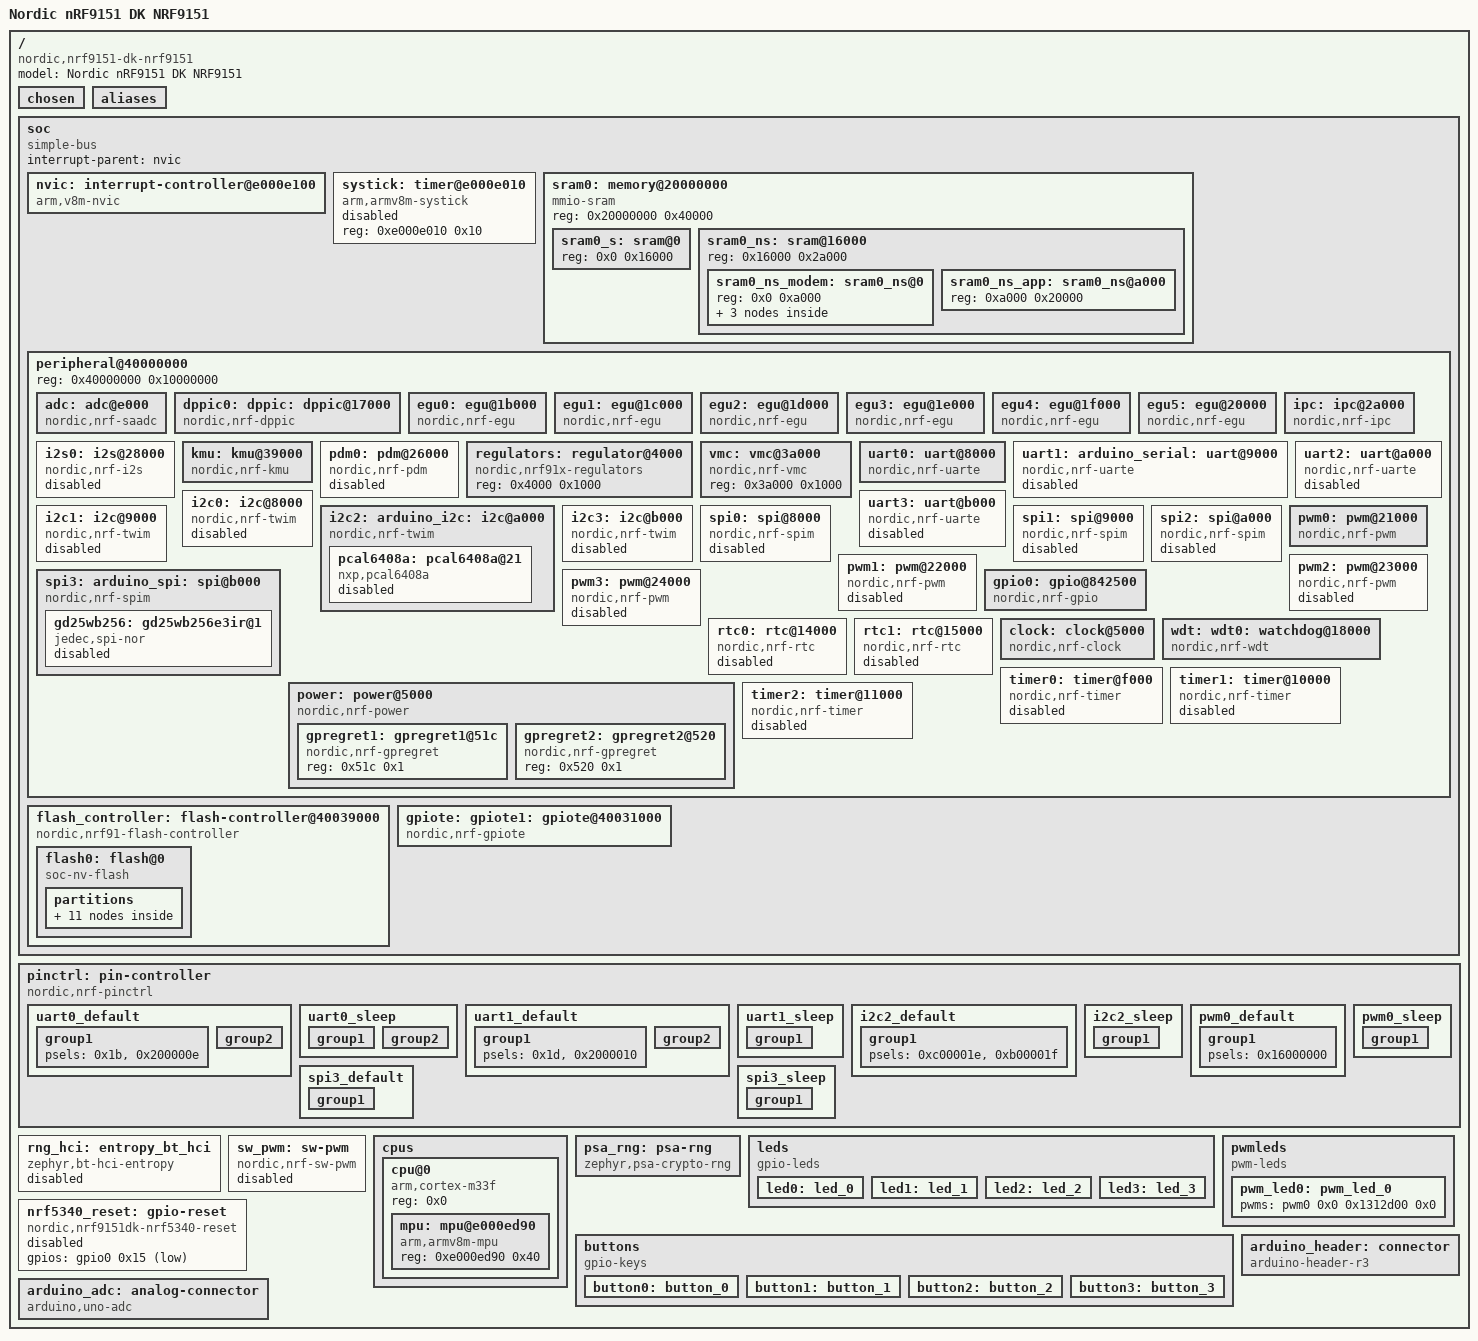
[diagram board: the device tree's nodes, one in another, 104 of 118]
/dts-v1/;

/* node '/' defined in zephyr/dts/common/skeleton.dtsi:9 */
/ {
	#address-cells = < 0x1 >;                 /* in zephyr/dts/common/skeleton.dtsi:10 */
	#size-cells = < 0x1 >;                    /* in zephyr/dts/common/skeleton.dtsi:11 */
	model = "Nordic nRF9151 DK NRF9151";      /* in zephyr/boards/nordic/nrf9151dk/nrf9151dk_nrf9151_common.dtsi:11 */
	compatible = "nordic,nrf9151-dk-nrf9151"; /* in zephyr/boards/nordic/nrf9151dk/nrf9151dk_nrf9151_common.dtsi:12 */

	/* node '/chosen' defined in zephyr/dts/common/skeleton.dtsi:13 */
	chosen {
		zephyr,entropy = &psa_rng;                   /* in zephyr/dts/arm/nordic/nrf91_ns.dtsi:31 */
		zephyr,flash-controller = &flash_controller; /* in zephyr/dts/arm/nordic/nrf91_ns.dtsi:32 */
		zephyr,console = &uart0;                     /* in zephyr/boards/nordic/nrf9151dk/nrf9151dk_nrf9151_common.dtsi:15 */
		zephyr,shell-uart = &uart0;                  /* in zephyr/boards/nordic/nrf9151dk/nrf9151dk_nrf9151_common.dtsi:16 */
		zephyr,uart-mcumgr = &uart0;                 /* in zephyr/boards/nordic/nrf9151dk/nrf9151dk_nrf9151_common.dtsi:17 */
		zephyr,flash = &flash0;                      /* in zephyr/boards/nordic/nrf9151dk/nrf9151dk_nrf9151_ns.dts:13 */
		zephyr,sram = &sram0_ns_app;                 /* in zephyr/boards/nordic/nrf9151dk/nrf9151dk_nrf9151_ns.dts:14 */
		zephyr,code-partition = &slot0_ns_partition; /* in zephyr/boards/nordic/nrf9151dk/nrf9151dk_nrf9151_ns.dts:15 */
	};

	/* node '/aliases' defined in zephyr/dts/common/skeleton.dtsi:15 */
	aliases {
		led0 = &led0;               /* in zephyr/boards/nordic/nrf9151dk/nrf9151dk_nrf9151_common.dtsi:128 */
		led1 = &led1;               /* in zephyr/boards/nordic/nrf9151dk/nrf9151dk_nrf9151_common.dtsi:129 */
		led2 = &led2;               /* in zephyr/boards/nordic/nrf9151dk/nrf9151dk_nrf9151_common.dtsi:130 */
		led3 = &led3;               /* in zephyr/boards/nordic/nrf9151dk/nrf9151dk_nrf9151_common.dtsi:131 */
		pwm-led0 = &pwm_led0;       /* in zephyr/boards/nordic/nrf9151dk/nrf9151dk_nrf9151_common.dtsi:132 */
		sw0 = &button0;             /* in zephyr/boards/nordic/nrf9151dk/nrf9151dk_nrf9151_common.dtsi:133 */
		sw1 = &button1;             /* in zephyr/boards/nordic/nrf9151dk/nrf9151dk_nrf9151_common.dtsi:134 */
		sw2 = &button2;             /* in zephyr/boards/nordic/nrf9151dk/nrf9151dk_nrf9151_common.dtsi:135 */
		sw3 = &button3;             /* in zephyr/boards/nordic/nrf9151dk/nrf9151dk_nrf9151_common.dtsi:136 */
		mcuboot-button0 = &button0; /* in zephyr/boards/nordic/nrf9151dk/nrf9151dk_nrf9151_common.dtsi:137 */
		mcuboot-led0 = &led0;       /* in zephyr/boards/nordic/nrf9151dk/nrf9151dk_nrf9151_common.dtsi:138 */
		watchdog0 = &wdt0;          /* in zephyr/boards/nordic/nrf9151dk/nrf9151dk_nrf9151_common.dtsi:139 */
	};

	/* node '/soc' defined in zephyr/dts/arm/armv8-m.dtsi:6 */
	soc {
		#address-cells = < 0x1 >;     /* in zephyr/dts/arm/armv8-m.dtsi:7 */
		#size-cells = < 0x1 >;        /* in zephyr/dts/arm/armv8-m.dtsi:8 */
		interrupt-parent = < &nvic >; /* in zephyr/dts/arm/armv8-m.dtsi:10 */
		ranges;                       /* in zephyr/dts/arm/armv8-m.dtsi:11 */
		compatible = "simple-bus";    /* in zephyr/dts/arm/nordic/nrf91_ns.dtsi:36 */

		/* node '/soc/interrupt-controller@e000e100' defined in zephyr/dts/arm/armv8-m.dtsi:13 */
		nvic: interrupt-controller@e000e100 {
			#address-cells = < 0x1 >;            /* in zephyr/dts/arm/armv8-m.dtsi:14 */
			compatible = "arm,v8m-nvic";         /* in zephyr/dts/arm/armv8-m.dtsi:15 */
			reg = < 0xe000e100 0xc00 >;          /* in zephyr/dts/arm/armv8-m.dtsi:16 */
			interrupt-controller;                /* in zephyr/dts/arm/armv8-m.dtsi:17 */
			#interrupt-cells = < 0x2 >;          /* in zephyr/dts/arm/armv8-m.dtsi:18 */
			arm,num-irq-priority-bits = < 0x3 >; /* in zephyr/dts/arm/nordic/nrf91_ns.dtsi:95 */
			phandle = < 0x1 >;                   /* in zephyr/dts/arm/armv8-m.dtsi:10 */
		};

		/* node '/soc/timer@e000e010' defined in zephyr/dts/arm/armv8-m.dtsi:21 */
		systick: timer@e000e010 {
			compatible = "arm,armv8m-systick"; /* in zephyr/dts/arm/armv8-m.dtsi:22 */
			reg = < 0xe000e010 0x10 >;         /* in zephyr/dts/arm/armv8-m.dtsi:23 */
			status = "disabled";               /* in zephyr/dts/arm/nordic/nrf91_ns.dtsi:100 */
		};

		/* node '/soc/memory@20000000' defined in zephyr/dts/arm/nordic/nrf91_ns.dtsi:38 */
		sram0: memory@20000000 {
			compatible = "mmio-sram";            /* in zephyr/dts/arm/nordic/nrf91_ns.dtsi:39 */
			#address-cells = < 0x1 >;            /* in zephyr/dts/arm/nordic/nrf91_ns.dtsi:40 */
			#size-cells = < 0x1 >;               /* in zephyr/dts/arm/nordic/nrf91_ns.dtsi:41 */
			reg = < 0x20000000 0x40000 >;        /* in zephyr/dts/arm/nordic/nrf9151_ns_laca.dtsi:11 */
			ranges = < 0x0 0x20000000 0x40000 >; /* in zephyr/dts/arm/nordic/nrf9151_ns_laca.dtsi:12 */

			/* node '/soc/memory@20000000/sram@0' defined in zephyr/dts/vendor/nordic/nrf91xx_partition.dtsi:116 */
			sram0_s: sram@0 {
				reg = < 0x0 0x16000 >; /* in zephyr/dts/vendor/nordic/nrf91xx_partition.dtsi:118 */
			};

			/* node '/soc/memory@20000000/sram@16000' defined in zephyr/dts/vendor/nordic/nrf91xx_partition.dtsi:121 */
			sram0_ns: sram@16000 {
				reg = < 0x16000 0x2a000 >;        /* in zephyr/dts/vendor/nordic/nrf91xx_partition.dtsi:123 */
				#address-cells = < 0x1 >;         /* in zephyr/dts/vendor/nordic/nrf91xx_partition.dtsi:124 */
				#size-cells = < 0x1 >;            /* in zephyr/dts/vendor/nordic/nrf91xx_partition.dtsi:125 */
				ranges = < 0x0 0x16000 0x2a000 >; /* in zephyr/dts/vendor/nordic/nrf91xx_partition.dtsi:126 */

				/* node '/soc/memory@20000000/sram@16000/sram0_ns@0' defined in zephyr/dts/vendor/nordic/nrf91xx_partition.dtsi:128 */
				sram0_ns_modem: sram0_ns@0 {
					reg = < 0x0 0xa000 >;        /* in zephyr/dts/vendor/nordic/nrf91xx_partition.dtsi:130 */
					#address-cells = < 0x1 >;    /* in zephyr/dts/vendor/nordic/nrf91xx_partition.dtsi:131 */
					#size-cells = < 0x1 >;       /* in zephyr/dts/vendor/nordic/nrf91xx_partition.dtsi:132 */
					ranges = < 0x0 0x0 0xa000 >; /* in zephyr/dts/vendor/nordic/nrf91xx_partition.dtsi:133 */

					/* node '/soc/memory@20000000/sram@16000/sram0_ns@0/sram0_ns_modem@0' defined in zephyr/dts/vendor/nordic/nrf91xx_partition.dtsi:135 */
					cpuapp_cpucell_ipc_shm_ctrl: sram0_ns_modem@0 {
						reg = < 0x0 0x4e8 >; /* in zephyr/dts/vendor/nordic/nrf91xx_partition.dtsi:137 */
					};

					/* node '/soc/memory@20000000/sram@16000/sram0_ns@0/sram0_ns_modem@4e8' defined in zephyr/dts/vendor/nordic/nrf91xx_partition.dtsi:140 */
					cpuapp_cpucell_ipc_shm_heap: sram0_ns_modem@4e8 {
						reg = < 0x4e8 0x2080 >; /* in zephyr/dts/vendor/nordic/nrf91xx_partition.dtsi:142 */
					};

					/* node '/soc/memory@20000000/sram@16000/sram0_ns@0/sram0_ns_modem@2568' defined in zephyr/dts/vendor/nordic/nrf91xx_partition.dtsi:145 */
					cpucell_cpuapp_ipc_shm_heap: sram0_ns_modem@2568 {
						reg = < 0x2568 0x2000 >; /* in zephyr/dts/vendor/nordic/nrf91xx_partition.dtsi:147 */
					};
				};

				/* node '/soc/memory@20000000/sram@16000/sram0_ns@a000' defined in zephyr/dts/vendor/nordic/nrf91xx_partition.dtsi:151 */
				sram0_ns_app: sram0_ns@a000 {
					reg = < 0xa000 0x20000 >; /* in zephyr/dts/vendor/nordic/nrf91xx_partition.dtsi:153 */
				};
			};
		};

		/* node '/soc/peripheral@40000000' defined in zephyr/dts/arm/nordic/nrf91_ns.dtsi:44 */
		peripheral@40000000 {
			#address-cells = < 0x1 >;               /* in zephyr/dts/arm/nordic/nrf91_ns.dtsi:45 */
			#size-cells = < 0x1 >;                  /* in zephyr/dts/arm/nordic/nrf91_ns.dtsi:46 */
			reg = < 0x40000000 0x10000000 >;        /* in zephyr/dts/arm/nordic/nrf91_ns.dtsi:47 */
			ranges = < 0x0 0x40000000 0x10000000 >; /* in zephyr/dts/arm/nordic/nrf91_ns.dtsi:48 */

			/* node '/soc/peripheral@40000000/adc@e000' defined in zephyr/dts/arm/nordic/nrf91_peripherals.dtsi:7 */
			adc: adc@e000 {
				compatible = "nordic,nrf-saadc"; /* in zephyr/dts/arm/nordic/nrf91_peripherals.dtsi:8 */
				reg = < 0xe000 0x1000 >;         /* in zephyr/dts/arm/nordic/nrf91_peripherals.dtsi:9 */
				interrupts = < 0xe 0x1 >;        /* in zephyr/dts/arm/nordic/nrf91_peripherals.dtsi:10 */
				#io-channel-cells = < 0x1 >;     /* in zephyr/dts/arm/nordic/nrf91_peripherals.dtsi:12 */
				zephyr,pm-device-runtime-auto;   /* in zephyr/dts/arm/nordic/nrf91_peripherals.dtsi:13 */
				status = "okay";                 /* in zephyr/boards/nordic/nrf9151dk/nrf9151dk_nrf9151_common.dtsi:144 */
				phandle = < 0x11 >;              /* in zephyr/boards/nordic/nrf9151dk/nrf9151dk_nrf9151_common.dtsi:118 */
			};

			/* node '/soc/peripheral@40000000/dppic@17000' defined in zephyr/dts/arm/nordic/nrf91_peripherals.dtsi:16 */
			dppic0: dppic: dppic@17000 {
				compatible = "nordic,nrf-dppic"; /* in zephyr/dts/arm/nordic/nrf91_peripherals.dtsi:17 */
				reg = < 0x17000 0x1000 >;        /* in zephyr/dts/arm/nordic/nrf91_peripherals.dtsi:18 */
				status = "okay";                 /* in zephyr/dts/arm/nordic/nrf91_peripherals.dtsi:19 */
				channels = < 0x10 >;             /* in zephyr/dts/arm/nordic/nrf91_peripherals.dtsi:20 */
				groups = < 0x6 >;                /* in zephyr/dts/arm/nordic/nrf91_peripherals.dtsi:21 */
			};

			/* node '/soc/peripheral@40000000/egu@1b000' defined in zephyr/dts/arm/nordic/nrf91_peripherals.dtsi:24 */
			egu0: egu@1b000 {
				compatible = "nordic,nrf-egu"; /* in zephyr/dts/arm/nordic/nrf91_peripherals.dtsi:25 */
				reg = < 0x1b000 0x1000 >;      /* in zephyr/dts/arm/nordic/nrf91_peripherals.dtsi:26 */
				interrupts = < 0x1b 0x1 >;     /* in zephyr/dts/arm/nordic/nrf91_peripherals.dtsi:27 */
				status = "okay";               /* in zephyr/dts/arm/nordic/nrf91_peripherals.dtsi:28 */
			};

			/* node '/soc/peripheral@40000000/egu@1c000' defined in zephyr/dts/arm/nordic/nrf91_peripherals.dtsi:31 */
			egu1: egu@1c000 {
				compatible = "nordic,nrf-egu"; /* in zephyr/dts/arm/nordic/nrf91_peripherals.dtsi:32 */
				reg = < 0x1c000 0x1000 >;      /* in zephyr/dts/arm/nordic/nrf91_peripherals.dtsi:33 */
				interrupts = < 0x1c 0x1 >;     /* in zephyr/dts/arm/nordic/nrf91_peripherals.dtsi:34 */
				status = "okay";               /* in zephyr/dts/arm/nordic/nrf91_peripherals.dtsi:35 */
			};

			/* node '/soc/peripheral@40000000/egu@1d000' defined in zephyr/dts/arm/nordic/nrf91_peripherals.dtsi:38 */
			egu2: egu@1d000 {
				compatible = "nordic,nrf-egu"; /* in zephyr/dts/arm/nordic/nrf91_peripherals.dtsi:39 */
				reg = < 0x1d000 0x1000 >;      /* in zephyr/dts/arm/nordic/nrf91_peripherals.dtsi:40 */
				interrupts = < 0x1d 0x1 >;     /* in zephyr/dts/arm/nordic/nrf91_peripherals.dtsi:41 */
				status = "okay";               /* in zephyr/dts/arm/nordic/nrf91_peripherals.dtsi:42 */
			};

			/* node '/soc/peripheral@40000000/egu@1e000' defined in zephyr/dts/arm/nordic/nrf91_peripherals.dtsi:45 */
			egu3: egu@1e000 {
				compatible = "nordic,nrf-egu"; /* in zephyr/dts/arm/nordic/nrf91_peripherals.dtsi:46 */
				reg = < 0x1e000 0x1000 >;      /* in zephyr/dts/arm/nordic/nrf91_peripherals.dtsi:47 */
				interrupts = < 0x1e 0x1 >;     /* in zephyr/dts/arm/nordic/nrf91_peripherals.dtsi:48 */
				status = "okay";               /* in zephyr/dts/arm/nordic/nrf91_peripherals.dtsi:49 */
			};

			/* node '/soc/peripheral@40000000/egu@1f000' defined in zephyr/dts/arm/nordic/nrf91_peripherals.dtsi:52 */
			egu4: egu@1f000 {
				compatible = "nordic,nrf-egu"; /* in zephyr/dts/arm/nordic/nrf91_peripherals.dtsi:53 */
				reg = < 0x1f000 0x1000 >;      /* in zephyr/dts/arm/nordic/nrf91_peripherals.dtsi:54 */
				interrupts = < 0x1f 0x1 >;     /* in zephyr/dts/arm/nordic/nrf91_peripherals.dtsi:55 */
				status = "okay";               /* in zephyr/dts/arm/nordic/nrf91_peripherals.dtsi:56 */
			};

			/* node '/soc/peripheral@40000000/egu@20000' defined in zephyr/dts/arm/nordic/nrf91_peripherals.dtsi:59 */
			egu5: egu@20000 {
				compatible = "nordic,nrf-egu"; /* in zephyr/dts/arm/nordic/nrf91_peripherals.dtsi:60 */
				reg = < 0x20000 0x1000 >;      /* in zephyr/dts/arm/nordic/nrf91_peripherals.dtsi:61 */
				interrupts = < 0x20 0x1 >;     /* in zephyr/dts/arm/nordic/nrf91_peripherals.dtsi:62 */
				status = "okay";               /* in zephyr/dts/arm/nordic/nrf91_peripherals.dtsi:63 */
			};

			/* node '/soc/peripheral@40000000/ipc@2a000' defined in zephyr/dts/arm/nordic/nrf91_peripherals.dtsi:66 */
			ipc: ipc@2a000 {
				compatible = "nordic,nrf-ipc"; /* in zephyr/dts/arm/nordic/nrf91_peripherals.dtsi:67 */
				reg = < 0x2a000 0x1000 >;      /* in zephyr/dts/arm/nordic/nrf91_peripherals.dtsi:68 */
				interrupts = < 0x2a 0x1 >;     /* in zephyr/dts/arm/nordic/nrf91_peripherals.dtsi:69 */
				status = "okay";               /* in zephyr/dts/arm/nordic/nrf91_peripherals.dtsi:70 */
			};

			/* node '/soc/peripheral@40000000/i2s@28000' defined in zephyr/dts/arm/nordic/nrf91_peripherals.dtsi:73 */
			i2s0: i2s@28000 {
				compatible = "nordic,nrf-i2s"; /* in zephyr/dts/arm/nordic/nrf91_peripherals.dtsi:74 */
				#address-cells = < 0x1 >;      /* in zephyr/dts/arm/nordic/nrf91_peripherals.dtsi:75 */
				#size-cells = < 0x0 >;         /* in zephyr/dts/arm/nordic/nrf91_peripherals.dtsi:76 */
				reg = < 0x28000 0x1000 >;      /* in zephyr/dts/arm/nordic/nrf91_peripherals.dtsi:77 */
				interrupts = < 0x28 0x1 >;     /* in zephyr/dts/arm/nordic/nrf91_peripherals.dtsi:78 */
				status = "disabled";           /* in zephyr/dts/arm/nordic/nrf91_peripherals.dtsi:79 */
			};

			/* node '/soc/peripheral@40000000/kmu@39000' defined in zephyr/dts/arm/nordic/nrf91_peripherals.dtsi:82 */
			kmu: kmu@39000 {
				compatible = "nordic,nrf-kmu"; /* in zephyr/dts/arm/nordic/nrf91_peripherals.dtsi:83 */
				reg = < 0x39000 0x1000 >;      /* in zephyr/dts/arm/nordic/nrf91_peripherals.dtsi:84 */
				interrupts = < 0x39 0x1 >;     /* in zephyr/dts/arm/nordic/nrf91_peripherals.dtsi:85 */
				status = "okay";               /* in zephyr/dts/arm/nordic/nrf91_peripherals.dtsi:86 */
			};

			/* node '/soc/peripheral@40000000/pdm@26000' defined in zephyr/dts/arm/nordic/nrf91_peripherals.dtsi:89 */
			pdm0: pdm@26000 {
				compatible = "nordic,nrf-pdm"; /* in zephyr/dts/arm/nordic/nrf91_peripherals.dtsi:90 */
				reg = < 0x26000 0x1000 >;      /* in zephyr/dts/arm/nordic/nrf91_peripherals.dtsi:91 */
				interrupts = < 0x26 0x1 >;     /* in zephyr/dts/arm/nordic/nrf91_peripherals.dtsi:92 */
				status = "disabled";           /* in zephyr/dts/arm/nordic/nrf91_peripherals.dtsi:93 */
			};

			/* node '/soc/peripheral@40000000/regulator@4000' defined in zephyr/dts/arm/nordic/nrf91_peripherals.dtsi:96 */
			regulators: regulator@4000 {
				compatible = "nordic,nrf91x-regulators"; /* in zephyr/dts/arm/nordic/nrf91_peripherals.dtsi:97 */
				reg = < 0x4000 0x1000 >;                 /* in zephyr/dts/arm/nordic/nrf91_peripherals.dtsi:98 */
				status = "okay";                         /* in zephyr/dts/arm/nordic/nrf91_peripherals.dtsi:99 */
			};

			/* node '/soc/peripheral@40000000/vmc@3a000' defined in zephyr/dts/arm/nordic/nrf91_peripherals.dtsi:102 */
			vmc: vmc@3a000 {
				compatible = "nordic,nrf-vmc"; /* in zephyr/dts/arm/nordic/nrf91_peripherals.dtsi:103 */
				reg = < 0x3a000 0x1000 >;      /* in zephyr/dts/arm/nordic/nrf91_peripherals.dtsi:104 */
				status = "okay";               /* in zephyr/dts/arm/nordic/nrf91_peripherals.dtsi:105 */
			};

			/* node '/soc/peripheral@40000000/uart@8000' defined in zephyr/dts/arm/nordic/nrf91_peripherals.dtsi:108 */
			uart0: uart@8000 {
				compatible = "nordic,nrf-uarte"; /* in zephyr/dts/arm/nordic/nrf91_peripherals.dtsi:109 */
				reg = < 0x8000 0x1000 >;         /* in zephyr/dts/arm/nordic/nrf91_peripherals.dtsi:110 */
				interrupts = < 0x8 0x1 >;        /* in zephyr/dts/arm/nordic/nrf91_peripherals.dtsi:111 */
				status = "okay";                 /* in zephyr/boards/nordic/nrf9151dk/nrf9151dk_nrf9151_common.dtsi:156 */
				current-speed = < 0x1c200 >;     /* in zephyr/boards/nordic/nrf9151dk/nrf9151dk_nrf9151_common.dtsi:157 */
				pinctrl-0 = < &uart0_default >;  /* in zephyr/boards/nordic/nrf9151dk/nrf9151dk_nrf9151_common.dtsi:158 */
				pinctrl-1 = < &uart0_sleep >;    /* in zephyr/boards/nordic/nrf9151dk/nrf9151dk_nrf9151_common.dtsi:159 */
				pinctrl-names = "default",
				                "sleep";         /* in zephyr/boards/nordic/nrf9151dk/nrf9151dk_nrf9151_common.dtsi:160 */
			};

			/* node '/soc/peripheral@40000000/uart@9000' defined in zephyr/dts/arm/nordic/nrf91_peripherals.dtsi:115 */
			uart1: arduino_serial: uart@9000 {
				compatible = "nordic,nrf-uarte"; /* in zephyr/dts/arm/nordic/nrf91_peripherals.dtsi:116 */
				reg = < 0x9000 0x1000 >;         /* in zephyr/dts/arm/nordic/nrf91_peripherals.dtsi:117 */
				interrupts = < 0x9 0x1 >;        /* in zephyr/dts/arm/nordic/nrf91_peripherals.dtsi:118 */
				current-speed = < 0x1c200 >;     /* in zephyr/boards/nordic/nrf9151dk/nrf9151dk_nrf9151_common.dtsi:165 */
				pinctrl-0 = < &uart1_default >;  /* in zephyr/boards/nordic/nrf9151dk/nrf9151dk_nrf9151_common.dtsi:166 */
				pinctrl-1 = < &uart1_sleep >;    /* in zephyr/boards/nordic/nrf9151dk/nrf9151dk_nrf9151_common.dtsi:167 */
				pinctrl-names = "default",
				                "sleep";         /* in zephyr/boards/nordic/nrf9151dk/nrf9151dk_nrf9151_common.dtsi:168 */
				status = "disabled";             /* in zephyr/boards/nordic/nrf9151dk/nrf9151dk_nrf9151_ns.dts:21 */
			};

			/* node '/soc/peripheral@40000000/uart@a000' defined in zephyr/dts/arm/nordic/nrf91_peripherals.dtsi:122 */
			uart2: uart@a000 {
				compatible = "nordic,nrf-uarte"; /* in zephyr/dts/arm/nordic/nrf91_peripherals.dtsi:123 */
				reg = < 0xa000 0x1000 >;         /* in zephyr/dts/arm/nordic/nrf91_peripherals.dtsi:124 */
				interrupts = < 0xa 0x1 >;        /* in zephyr/dts/arm/nordic/nrf91_peripherals.dtsi:125 */
				status = "disabled";             /* in zephyr/dts/arm/nordic/nrf91_peripherals.dtsi:126 */
			};

			/* node '/soc/peripheral@40000000/uart@b000' defined in zephyr/dts/arm/nordic/nrf91_peripherals.dtsi:129 */
			uart3: uart@b000 {
				compatible = "nordic,nrf-uarte"; /* in zephyr/dts/arm/nordic/nrf91_peripherals.dtsi:130 */
				reg = < 0xb000 0x1000 >;         /* in zephyr/dts/arm/nordic/nrf91_peripherals.dtsi:131 */
				interrupts = < 0xb 0x1 >;        /* in zephyr/dts/arm/nordic/nrf91_peripherals.dtsi:132 */
				status = "disabled";             /* in zephyr/dts/arm/nordic/nrf91_peripherals.dtsi:133 */
			};

			/* node '/soc/peripheral@40000000/i2c@8000' defined in zephyr/dts/arm/nordic/nrf91_peripherals.dtsi:136 */
			i2c0: i2c@8000 {
				compatible = "nordic,nrf-twim"; /* in zephyr/dts/arm/nordic/nrf91_peripherals.dtsi:142 */
				#address-cells = < 0x1 >;       /* in zephyr/dts/arm/nordic/nrf91_peripherals.dtsi:143 */
				#size-cells = < 0x0 >;          /* in zephyr/dts/arm/nordic/nrf91_peripherals.dtsi:144 */
				reg = < 0x8000 0x1000 >;        /* in zephyr/dts/arm/nordic/nrf91_peripherals.dtsi:145 */
				interrupts = < 0x8 0x1 >;       /* in zephyr/dts/arm/nordic/nrf91_peripherals.dtsi:146 */
				easydma-maxcnt-bits = < 0xd >;  /* in zephyr/dts/arm/nordic/nrf91_peripherals.dtsi:147 */
				status = "disabled";            /* in zephyr/dts/arm/nordic/nrf91_peripherals.dtsi:148 */
				zephyr,pm-device-runtime-auto;  /* in zephyr/dts/arm/nordic/nrf91_peripherals.dtsi:149 */
			};

			/* node '/soc/peripheral@40000000/i2c@9000' defined in zephyr/dts/arm/nordic/nrf91_peripherals.dtsi:152 */
			i2c1: i2c@9000 {
				compatible = "nordic,nrf-twim"; /* in zephyr/dts/arm/nordic/nrf91_peripherals.dtsi:158 */
				#address-cells = < 0x1 >;       /* in zephyr/dts/arm/nordic/nrf91_peripherals.dtsi:159 */
				#size-cells = < 0x0 >;          /* in zephyr/dts/arm/nordic/nrf91_peripherals.dtsi:160 */
				reg = < 0x9000 0x1000 >;        /* in zephyr/dts/arm/nordic/nrf91_peripherals.dtsi:161 */
				interrupts = < 0x9 0x1 >;       /* in zephyr/dts/arm/nordic/nrf91_peripherals.dtsi:162 */
				easydma-maxcnt-bits = < 0xd >;  /* in zephyr/dts/arm/nordic/nrf91_peripherals.dtsi:163 */
				status = "disabled";            /* in zephyr/dts/arm/nordic/nrf91_peripherals.dtsi:164 */
				zephyr,pm-device-runtime-auto;  /* in zephyr/dts/arm/nordic/nrf91_peripherals.dtsi:165 */
			};

			/* node '/soc/peripheral@40000000/i2c@a000' defined in zephyr/dts/arm/nordic/nrf91_peripherals.dtsi:168 */
			i2c2: arduino_i2c: i2c@a000 {
				#address-cells = < 0x1 >;       /* in zephyr/dts/arm/nordic/nrf91_peripherals.dtsi:175 */
				#size-cells = < 0x0 >;          /* in zephyr/dts/arm/nordic/nrf91_peripherals.dtsi:176 */
				reg = < 0xa000 0x1000 >;        /* in zephyr/dts/arm/nordic/nrf91_peripherals.dtsi:177 */
				interrupts = < 0xa 0x1 >;       /* in zephyr/dts/arm/nordic/nrf91_peripherals.dtsi:178 */
				easydma-maxcnt-bits = < 0xd >;  /* in zephyr/dts/arm/nordic/nrf91_peripherals.dtsi:179 */
				zephyr,pm-device-runtime-auto;  /* in zephyr/dts/arm/nordic/nrf91_peripherals.dtsi:181 */
				compatible = "nordic,nrf-twim"; /* in zephyr/boards/nordic/nrf9151dk/nrf9151dk_nrf9151_common.dtsi:172 */
				status = "okay";                /* in zephyr/boards/nordic/nrf9151dk/nrf9151dk_nrf9151_common.dtsi:173 */
				pinctrl-0 = < &i2c2_default >;  /* in zephyr/boards/nordic/nrf9151dk/nrf9151dk_nrf9151_common.dtsi:174 */
				pinctrl-1 = < &i2c2_sleep >;    /* in zephyr/boards/nordic/nrf9151dk/nrf9151dk_nrf9151_common.dtsi:175 */
				pinctrl-names = "default",
				                "sleep";        /* in zephyr/boards/nordic/nrf9151dk/nrf9151dk_nrf9151_common.dtsi:176 */
				clock-frequency = < 0x61a80 >;  /* in zephyr/boards/nordic/nrf9151dk/nrf9151dk_nrf9151_common.dtsi:177 */

				/* node '/soc/peripheral@40000000/i2c@a000/pcal6408a@21' defined in zephyr/boards/nordic/nrf9151dk/nrf9151dk_nrf9151_common.dtsi:179 */
				pcal6408a: pcal6408a@21 {
					compatible = "nxp,pcal6408a";     /* in zephyr/boards/nordic/nrf9151dk/nrf9151dk_nrf9151_common.dtsi:180 */
					status = "disabled";              /* in zephyr/boards/nordic/nrf9151dk/nrf9151dk_nrf9151_common.dtsi:181 */
					reg = < 0x21 >;                   /* in zephyr/boards/nordic/nrf9151dk/nrf9151dk_nrf9151_common.dtsi:182 */
					gpio-controller;                  /* in zephyr/boards/nordic/nrf9151dk/nrf9151dk_nrf9151_common.dtsi:183 */
					#gpio-cells = < 0x2 >;            /* in zephyr/boards/nordic/nrf9151dk/nrf9151dk_nrf9151_common.dtsi:184 */
					ngpios = < 0x8 >;                 /* in zephyr/boards/nordic/nrf9151dk/nrf9151dk_nrf9151_common.dtsi:185 */
					int-gpios = < &gpio0 0x13 0x11 >; /* in zephyr/boards/nordic/nrf9151dk/nrf9151dk_nrf9151_common.dtsi:186 */
				};
			};

			/* node '/soc/peripheral@40000000/i2c@b000' defined in zephyr/dts/arm/nordic/nrf91_peripherals.dtsi:184 */
			i2c3: i2c@b000 {
				compatible = "nordic,nrf-twim"; /* in zephyr/dts/arm/nordic/nrf91_peripherals.dtsi:190 */
				#address-cells = < 0x1 >;       /* in zephyr/dts/arm/nordic/nrf91_peripherals.dtsi:191 */
				#size-cells = < 0x0 >;          /* in zephyr/dts/arm/nordic/nrf91_peripherals.dtsi:192 */
				reg = < 0xb000 0x1000 >;        /* in zephyr/dts/arm/nordic/nrf91_peripherals.dtsi:193 */
				interrupts = < 0xb 0x1 >;       /* in zephyr/dts/arm/nordic/nrf91_peripherals.dtsi:194 */
				easydma-maxcnt-bits = < 0xd >;  /* in zephyr/dts/arm/nordic/nrf91_peripherals.dtsi:195 */
				status = "disabled";            /* in zephyr/dts/arm/nordic/nrf91_peripherals.dtsi:196 */
				zephyr,pm-device-runtime-auto;  /* in zephyr/dts/arm/nordic/nrf91_peripherals.dtsi:197 */
			};

			/* node '/soc/peripheral@40000000/spi@8000' defined in zephyr/dts/arm/nordic/nrf91_peripherals.dtsi:200 */
			spi0: spi@8000 {
				compatible = "nordic,nrf-spim"; /* in zephyr/dts/arm/nordic/nrf91_peripherals.dtsi:206 */
				#address-cells = < 0x1 >;       /* in zephyr/dts/arm/nordic/nrf91_peripherals.dtsi:207 */
				#size-cells = < 0x0 >;          /* in zephyr/dts/arm/nordic/nrf91_peripherals.dtsi:208 */
				reg = < 0x8000 0x1000 >;        /* in zephyr/dts/arm/nordic/nrf91_peripherals.dtsi:209 */
				interrupts = < 0x8 0x1 >;       /* in zephyr/dts/arm/nordic/nrf91_peripherals.dtsi:210 */
				max-frequency = < 0x7a1200 >;   /* in zephyr/dts/arm/nordic/nrf91_peripherals.dtsi:211 */
				easydma-maxcnt-bits = < 0xd >;  /* in zephyr/dts/arm/nordic/nrf91_peripherals.dtsi:212 */
				status = "disabled";            /* in zephyr/dts/arm/nordic/nrf91_peripherals.dtsi:213 */
			};

			/* node '/soc/peripheral@40000000/spi@9000' defined in zephyr/dts/arm/nordic/nrf91_peripherals.dtsi:216 */
			spi1: spi@9000 {
				compatible = "nordic,nrf-spim"; /* in zephyr/dts/arm/nordic/nrf91_peripherals.dtsi:222 */
				#address-cells = < 0x1 >;       /* in zephyr/dts/arm/nordic/nrf91_peripherals.dtsi:223 */
				#size-cells = < 0x0 >;          /* in zephyr/dts/arm/nordic/nrf91_peripherals.dtsi:224 */
				reg = < 0x9000 0x1000 >;        /* in zephyr/dts/arm/nordic/nrf91_peripherals.dtsi:225 */
				interrupts = < 0x9 0x1 >;       /* in zephyr/dts/arm/nordic/nrf91_peripherals.dtsi:226 */
				max-frequency = < 0x7a1200 >;   /* in zephyr/dts/arm/nordic/nrf91_peripherals.dtsi:227 */
				easydma-maxcnt-bits = < 0xd >;  /* in zephyr/dts/arm/nordic/nrf91_peripherals.dtsi:228 */
				status = "disabled";            /* in zephyr/dts/arm/nordic/nrf91_peripherals.dtsi:229 */
			};

			/* node '/soc/peripheral@40000000/spi@a000' defined in zephyr/dts/arm/nordic/nrf91_peripherals.dtsi:232 */
			spi2: spi@a000 {
				compatible = "nordic,nrf-spim"; /* in zephyr/dts/arm/nordic/nrf91_peripherals.dtsi:238 */
				#address-cells = < 0x1 >;       /* in zephyr/dts/arm/nordic/nrf91_peripherals.dtsi:239 */
				#size-cells = < 0x0 >;          /* in zephyr/dts/arm/nordic/nrf91_peripherals.dtsi:240 */
				reg = < 0xa000 0x1000 >;        /* in zephyr/dts/arm/nordic/nrf91_peripherals.dtsi:241 */
				interrupts = < 0xa 0x1 >;       /* in zephyr/dts/arm/nordic/nrf91_peripherals.dtsi:242 */
				max-frequency = < 0x7a1200 >;   /* in zephyr/dts/arm/nordic/nrf91_peripherals.dtsi:243 */
				easydma-maxcnt-bits = < 0xd >;  /* in zephyr/dts/arm/nordic/nrf91_peripherals.dtsi:244 */
				status = "disabled";            /* in zephyr/dts/arm/nordic/nrf91_peripherals.dtsi:245 */
			};

			/* node '/soc/peripheral@40000000/spi@b000' defined in zephyr/dts/arm/nordic/nrf91_peripherals.dtsi:248 */
			spi3: arduino_spi: spi@b000 {
				#address-cells = < 0x1 >;                /* in zephyr/dts/arm/nordic/nrf91_peripherals.dtsi:255 */
				#size-cells = < 0x0 >;                   /* in zephyr/dts/arm/nordic/nrf91_peripherals.dtsi:256 */
				reg = < 0xb000 0x1000 >;                 /* in zephyr/dts/arm/nordic/nrf91_peripherals.dtsi:257 */
				interrupts = < 0xb 0x1 >;                /* in zephyr/dts/arm/nordic/nrf91_peripherals.dtsi:258 */
				max-frequency = < 0x7a1200 >;            /* in zephyr/dts/arm/nordic/nrf91_peripherals.dtsi:259 */
				easydma-maxcnt-bits = < 0xd >;           /* in zephyr/dts/arm/nordic/nrf91_peripherals.dtsi:260 */
				compatible = "nordic,nrf-spim";          /* in zephyr/boards/nordic/nrf9151dk/nrf9151dk_nrf9151_common.dtsi:198 */
				status = "okay";                         /* in zephyr/boards/nordic/nrf9151dk/nrf9151dk_nrf9151_common.dtsi:199 */
				cs-gpios = < &arduino_header 0x10 0x1 >,
				           < &gpio0 0x14 0x1 >;          /* in zephyr/boards/nordic/nrf9151dk/nrf9151dk_nrf9151_common.dtsi:200 */
				pinctrl-0 = < &spi3_default >;           /* in zephyr/boards/nordic/nrf9151dk/nrf9151dk_nrf9151_common.dtsi:202 */
				pinctrl-1 = < &spi3_sleep >;             /* in zephyr/boards/nordic/nrf9151dk/nrf9151dk_nrf9151_common.dtsi:203 */
				pinctrl-names = "default",
				                "sleep";                 /* in zephyr/boards/nordic/nrf9151dk/nrf9151dk_nrf9151_common.dtsi:204 */

				/* node '/soc/peripheral@40000000/spi@b000/gd25wb256e3ir@1' defined in zephyr/boards/nordic/nrf9151dk/nrf9151dk_nrf9151_common.dtsi:206 */
				gd25wb256: gd25wb256e3ir@1 {
					compatible = "jedec,spi-nor";                                                                 /* in zephyr/boards/nordic/nrf9151dk/nrf9151dk_nrf9151_common.dtsi:207 */
					status = "disabled";                                                                          /* in zephyr/boards/nordic/nrf9151dk/nrf9151dk_nrf9151_common.dtsi:208 */
					reg = < 0x1 >;                                                                                /* in zephyr/boards/nordic/nrf9151dk/nrf9151dk_nrf9151_common.dtsi:209 */
					spi-max-frequency = < 0x7a1200 >;                                                             /* in zephyr/boards/nordic/nrf9151dk/nrf9151dk_nrf9151_common.dtsi:210 */
					size = < 0x10000000 >;                                                                        /* in zephyr/boards/nordic/nrf9151dk/nrf9151dk_nrf9151_common.dtsi:211 */
					has-dpd;                                                                                      /* in zephyr/boards/nordic/nrf9151dk/nrf9151dk_nrf9151_common.dtsi:212 */
					t-enter-dpd = < 0xbb8 >;                                                                      /* in zephyr/boards/nordic/nrf9151dk/nrf9151dk_nrf9151_common.dtsi:213 */
					t-exit-dpd = < 0x9c40 >;                                                                      /* in zephyr/boards/nordic/nrf9151dk/nrf9151dk_nrf9151_common.dtsi:214 */
					sfdp-bfp = [ E5 20 F3 FF FF FF FF 0F 44 EB 08 6B 08 3B 42 BB EE FF FF FF FF FF 00 FF FF FF 00
					             FF 0C 20 0F 52 10 D8 00 FF 44 7A C9 FE 83 67 26 62 EC 82 18 44 7A 75 7A 75 04 C4
					             D5 5C 00 06 74 00 08 50 00 01 ];                                                 /* in zephyr/boards/nordic/nrf9151dk/nrf9151dk_nrf9151_common.dtsi:215 */
					jedec-id = [ C8 65 19 ];                                                                      /* in zephyr/boards/nordic/nrf9151dk/nrf9151dk_nrf9151_common.dtsi:219 */
				};
			};

			/* node '/soc/peripheral@40000000/pwm@21000' defined in zephyr/dts/arm/nordic/nrf91_peripherals.dtsi:264 */
			pwm0: pwm@21000 {
				compatible = "nordic,nrf-pwm"; /* in zephyr/dts/arm/nordic/nrf91_peripherals.dtsi:265 */
				reg = < 0x21000 0x1000 >;      /* in zephyr/dts/arm/nordic/nrf91_peripherals.dtsi:266 */
				interrupts = < 0x21 0x1 >;     /* in zephyr/dts/arm/nordic/nrf91_peripherals.dtsi:267 */
				#pwm-cells = < 0x3 >;          /* in zephyr/dts/arm/nordic/nrf91_peripherals.dtsi:269 */
				status = "okay";               /* in zephyr/boards/nordic/nrf9151dk/nrf9151dk_nrf9151_common.dtsi:191 */
				pinctrl-0 = < &pwm0_default >; /* in zephyr/boards/nordic/nrf9151dk/nrf9151dk_nrf9151_common.dtsi:192 */
				pinctrl-1 = < &pwm0_sleep >;   /* in zephyr/boards/nordic/nrf9151dk/nrf9151dk_nrf9151_common.dtsi:193 */
				pinctrl-names = "default",
				                "sleep";       /* in zephyr/boards/nordic/nrf9151dk/nrf9151dk_nrf9151_common.dtsi:194 */
				phandle = < 0x10 >;            /* in zephyr/boards/nordic/nrf9151dk/nrf9151dk_nrf9151_common.dtsi:48 */
			};

			/* node '/soc/peripheral@40000000/pwm@22000' defined in zephyr/dts/arm/nordic/nrf91_peripherals.dtsi:272 */
			pwm1: pwm@22000 {
				compatible = "nordic,nrf-pwm"; /* in zephyr/dts/arm/nordic/nrf91_peripherals.dtsi:273 */
				reg = < 0x22000 0x1000 >;      /* in zephyr/dts/arm/nordic/nrf91_peripherals.dtsi:274 */
				interrupts = < 0x22 0x1 >;     /* in zephyr/dts/arm/nordic/nrf91_peripherals.dtsi:275 */
				status = "disabled";           /* in zephyr/dts/arm/nordic/nrf91_peripherals.dtsi:276 */
				#pwm-cells = < 0x3 >;          /* in zephyr/dts/arm/nordic/nrf91_peripherals.dtsi:277 */
			};

			/* node '/soc/peripheral@40000000/pwm@23000' defined in zephyr/dts/arm/nordic/nrf91_peripherals.dtsi:280 */
			pwm2: pwm@23000 {
				compatible = "nordic,nrf-pwm"; /* in zephyr/dts/arm/nordic/nrf91_peripherals.dtsi:281 */
				reg = < 0x23000 0x1000 >;      /* in zephyr/dts/arm/nordic/nrf91_peripherals.dtsi:282 */
				interrupts = < 0x23 0x1 >;     /* in zephyr/dts/arm/nordic/nrf91_peripherals.dtsi:283 */
				status = "disabled";           /* in zephyr/dts/arm/nordic/nrf91_peripherals.dtsi:284 */
				#pwm-cells = < 0x3 >;          /* in zephyr/dts/arm/nordic/nrf91_peripherals.dtsi:285 */
			};

			/* node '/soc/peripheral@40000000/pwm@24000' defined in zephyr/dts/arm/nordic/nrf91_peripherals.dtsi:288 */
			pwm3: pwm@24000 {
				compatible = "nordic,nrf-pwm"; /* in zephyr/dts/arm/nordic/nrf91_peripherals.dtsi:289 */
				reg = < 0x24000 0x1000 >;      /* in zephyr/dts/arm/nordic/nrf91_peripherals.dtsi:290 */
				interrupts = < 0x24 0x1 >;     /* in zephyr/dts/arm/nordic/nrf91_peripherals.dtsi:291 */
				status = "disabled";           /* in zephyr/dts/arm/nordic/nrf91_peripherals.dtsi:292 */
				#pwm-cells = < 0x3 >;          /* in zephyr/dts/arm/nordic/nrf91_peripherals.dtsi:293 */
			};

			/* node '/soc/peripheral@40000000/gpio@842500' defined in zephyr/dts/arm/nordic/nrf91_peripherals.dtsi:296 */
			gpio0: gpio@842500 {
				compatible = "nordic,nrf-gpio"; /* in zephyr/dts/arm/nordic/nrf91_peripherals.dtsi:297 */
				gpio-controller;                /* in zephyr/dts/arm/nordic/nrf91_peripherals.dtsi:298 */
				reg = < 0x842500 0x300 >;       /* in zephyr/dts/arm/nordic/nrf91_peripherals.dtsi:299 */
				#gpio-cells = < 0x2 >;          /* in zephyr/dts/arm/nordic/nrf91_peripherals.dtsi:300 */
				port = < 0x0 >;                 /* in zephyr/dts/arm/nordic/nrf91_peripherals.dtsi:302 */
				gpiote-instance = < &gpiote >;  /* in zephyr/dts/arm/nordic/nrf91_peripherals.dtsi:303 */
				status = "okay";                /* in zephyr/boards/nordic/nrf9151dk/nrf9151dk_nrf9151_common.dtsi:152 */
				phandle = < 0x8 >;              /* in zephyr/boards/nordic/nrf9151dk/nrf9151dk_nrf9151_common.dtsi:186 */
			};

			/* node '/soc/peripheral@40000000/rtc@14000' defined in zephyr/dts/arm/nordic/nrf91_peripherals.dtsi:306 */
			rtc0: rtc@14000 {
				compatible = "nordic,nrf-rtc"; /* in zephyr/dts/arm/nordic/nrf91_peripherals.dtsi:307 */
				reg = < 0x14000 0x1000 >;      /* in zephyr/dts/arm/nordic/nrf91_peripherals.dtsi:308 */
				cc-num = < 0x4 >;              /* in zephyr/dts/arm/nordic/nrf91_peripherals.dtsi:309 */
				interrupts = < 0x14 0x1 >;     /* in zephyr/dts/arm/nordic/nrf91_peripherals.dtsi:310 */
				status = "disabled";           /* in zephyr/dts/arm/nordic/nrf91_peripherals.dtsi:311 */
				clock-frequency = < 0x8000 >;  /* in zephyr/dts/arm/nordic/nrf91_peripherals.dtsi:312 */
				prescaler = < 0x1 >;           /* in zephyr/dts/arm/nordic/nrf91_peripherals.dtsi:313 */
			};

			/* node '/soc/peripheral@40000000/rtc@15000' defined in zephyr/dts/arm/nordic/nrf91_peripherals.dtsi:316 */
			rtc1: rtc@15000 {
				compatible = "nordic,nrf-rtc"; /* in zephyr/dts/arm/nordic/nrf91_peripherals.dtsi:317 */
				reg = < 0x15000 0x1000 >;      /* in zephyr/dts/arm/nordic/nrf91_peripherals.dtsi:318 */
				cc-num = < 0x4 >;              /* in zephyr/dts/arm/nordic/nrf91_peripherals.dtsi:319 */
				interrupts = < 0x15 0x1 >;     /* in zephyr/dts/arm/nordic/nrf91_peripherals.dtsi:320 */
				status = "disabled";           /* in zephyr/dts/arm/nordic/nrf91_peripherals.dtsi:321 */
				clock-frequency = < 0x8000 >;  /* in zephyr/dts/arm/nordic/nrf91_peripherals.dtsi:322 */
				prescaler = < 0x1 >;           /* in zephyr/dts/arm/nordic/nrf91_peripherals.dtsi:323 */
			};

			/* node '/soc/peripheral@40000000/clock@5000' defined in zephyr/dts/arm/nordic/nrf91_peripherals.dtsi:326 */
			clock: clock@5000 {
				compatible = "nordic,nrf-clock"; /* in zephyr/dts/arm/nordic/nrf91_peripherals.dtsi:327 */
				reg = < 0x5000 0x1000 >;         /* in zephyr/dts/arm/nordic/nrf91_peripherals.dtsi:328 */
				interrupts = < 0x5 0x1 >;        /* in zephyr/dts/arm/nordic/nrf91_peripherals.dtsi:329 */
				status = "okay";                 /* in zephyr/dts/arm/nordic/nrf91_peripherals.dtsi:330 */
			};

			/* node '/soc/peripheral@40000000/power@5000' defined in zephyr/dts/arm/nordic/nrf91_peripherals.dtsi:333 */
			power: power@5000 {
				compatible = "nordic,nrf-power"; /* in zephyr/dts/arm/nordic/nrf91_peripherals.dtsi:334 */
				reg = < 0x5000 0x1000 >;         /* in zephyr/dts/arm/nordic/nrf91_peripherals.dtsi:335 */
				ranges = < 0x0 0x5000 0x1000 >;  /* in zephyr/dts/arm/nordic/nrf91_peripherals.dtsi:336 */
				interrupts = < 0x5 0x1 >;        /* in zephyr/dts/arm/nordic/nrf91_peripherals.dtsi:337 */
				status = "okay";                 /* in zephyr/dts/arm/nordic/nrf91_peripherals.dtsi:338 */
				#address-cells = < 0x1 >;        /* in zephyr/dts/arm/nordic/nrf91_peripherals.dtsi:339 */
				#size-cells = < 0x1 >;           /* in zephyr/dts/arm/nordic/nrf91_peripherals.dtsi:340 */

				/* node '/soc/peripheral@40000000/power@5000/gpregret1@51c' defined in zephyr/dts/arm/nordic/nrf91_peripherals.dtsi:342 */
				gpregret1: gpregret1@51c {
					#address-cells = < 0x1 >;           /* in zephyr/dts/arm/nordic/nrf91_peripherals.dtsi:343 */
					#size-cells = < 0x1 >;              /* in zephyr/dts/arm/nordic/nrf91_peripherals.dtsi:344 */
					compatible = "nordic,nrf-gpregret"; /* in zephyr/dts/arm/nordic/nrf91_peripherals.dtsi:345 */
					reg = < 0x51c 0x1 >;                /* in zephyr/dts/arm/nordic/nrf91_peripherals.dtsi:346 */
					status = "okay";                    /* in zephyr/dts/arm/nordic/nrf91_peripherals.dtsi:347 */
				};

				/* node '/soc/peripheral@40000000/power@5000/gpregret2@520' defined in zephyr/dts/arm/nordic/nrf91_peripherals.dtsi:350 */
				gpregret2: gpregret2@520 {
					#address-cells = < 0x1 >;           /* in zephyr/dts/arm/nordic/nrf91_peripherals.dtsi:351 */
					#size-cells = < 0x1 >;              /* in zephyr/dts/arm/nordic/nrf91_peripherals.dtsi:352 */
					compatible = "nordic,nrf-gpregret"; /* in zephyr/dts/arm/nordic/nrf91_peripherals.dtsi:353 */
					reg = < 0x520 0x1 >;                /* in zephyr/dts/arm/nordic/nrf91_peripherals.dtsi:354 */
					status = "okay";                    /* in zephyr/dts/arm/nordic/nrf91_peripherals.dtsi:355 */
				};
			};

			/* node '/soc/peripheral@40000000/watchdog@18000' defined in zephyr/dts/arm/nordic/nrf91_peripherals.dtsi:359 */
			wdt: wdt0: watchdog@18000 {
				compatible = "nordic,nrf-wdt"; /* in zephyr/dts/arm/nordic/nrf91_peripherals.dtsi:360 */
				reg = < 0x18000 0x1000 >;      /* in zephyr/dts/arm/nordic/nrf91_peripherals.dtsi:361 */
				interrupts = < 0x18 0x1 >;     /* in zephyr/dts/arm/nordic/nrf91_peripherals.dtsi:362 */
				status = "okay";               /* in zephyr/dts/arm/nordic/nrf91_peripherals.dtsi:363 */
			};

			/* node '/soc/peripheral@40000000/timer@f000' defined in zephyr/dts/arm/nordic/nrf91_peripherals.dtsi:366 */
			timer0: timer@f000 {
				compatible = "nordic,nrf-timer"; /* in zephyr/dts/arm/nordic/nrf91_peripherals.dtsi:367 */
				status = "disabled";             /* in zephyr/dts/arm/nordic/nrf91_peripherals.dtsi:368 */
				reg = < 0xf000 0x1000 >;         /* in zephyr/dts/arm/nordic/nrf91_peripherals.dtsi:369 */
				cc-num = < 0x6 >;                /* in zephyr/dts/arm/nordic/nrf91_peripherals.dtsi:370 */
				max-bit-width = < 0x20 >;        /* in zephyr/dts/arm/nordic/nrf91_peripherals.dtsi:371 */
				interrupts = < 0xf 0x1 >;        /* in zephyr/dts/arm/nordic/nrf91_peripherals.dtsi:372 */
				prescaler = < 0x0 >;             /* in zephyr/dts/arm/nordic/nrf91_peripherals.dtsi:373 */
			};

			/* node '/soc/peripheral@40000000/timer@10000' defined in zephyr/dts/arm/nordic/nrf91_peripherals.dtsi:376 */
			timer1: timer@10000 {
				compatible = "nordic,nrf-timer"; /* in zephyr/dts/arm/nordic/nrf91_peripherals.dtsi:377 */
				status = "disabled";             /* in zephyr/dts/arm/nordic/nrf91_peripherals.dtsi:378 */
				reg = < 0x10000 0x1000 >;        /* in zephyr/dts/arm/nordic/nrf91_peripherals.dtsi:379 */
				cc-num = < 0x6 >;                /* in zephyr/dts/arm/nordic/nrf91_peripherals.dtsi:380 */
				max-bit-width = < 0x20 >;        /* in zephyr/dts/arm/nordic/nrf91_peripherals.dtsi:381 */
				interrupts = < 0x10 0x1 >;       /* in zephyr/dts/arm/nordic/nrf91_peripherals.dtsi:382 */
				prescaler = < 0x0 >;             /* in zephyr/dts/arm/nordic/nrf91_peripherals.dtsi:383 */
				phandle = < 0xf >;               /* in zephyr/dts/vendor/nordic/nrf_common.dtsi:42 */
			};

			/* node '/soc/peripheral@40000000/timer@11000' defined in zephyr/dts/arm/nordic/nrf91_peripherals.dtsi:386 */
			timer2: timer@11000 {
				compatible = "nordic,nrf-timer"; /* in zephyr/dts/arm/nordic/nrf91_peripherals.dtsi:387 */
				status = "disabled";             /* in zephyr/dts/arm/nordic/nrf91_peripherals.dtsi:388 */
				reg = < 0x11000 0x1000 >;        /* in zephyr/dts/arm/nordic/nrf91_peripherals.dtsi:389 */
				cc-num = < 0x6 >;                /* in zephyr/dts/arm/nordic/nrf91_peripherals.dtsi:390 */
				max-bit-width = < 0x20 >;        /* in zephyr/dts/arm/nordic/nrf91_peripherals.dtsi:391 */
				interrupts = < 0x11 0x1 >;       /* in zephyr/dts/arm/nordic/nrf91_peripherals.dtsi:392 */
				prescaler = < 0x0 >;             /* in zephyr/dts/arm/nordic/nrf91_peripherals.dtsi:393 */
			};
		};

		/* node '/soc/flash-controller@40039000' defined in zephyr/dts/arm/nordic/nrf91_ns.dtsi:54 */
		flash_controller: flash-controller@40039000 {
			compatible = "nordic,nrf91-flash-controller"; /* in zephyr/dts/arm/nordic/nrf91_ns.dtsi:55 */
			reg = < 0x40039000 0x1000 >;                  /* in zephyr/dts/arm/nordic/nrf91_ns.dtsi:56 */
			ranges;                                       /* in zephyr/dts/arm/nordic/nrf91_ns.dtsi:57 */
			partial-erase;                                /* in zephyr/dts/arm/nordic/nrf91_ns.dtsi:58 */
			#address-cells = < 0x1 >;                     /* in zephyr/dts/arm/nordic/nrf91_ns.dtsi:59 */
			#size-cells = < 0x1 >;                        /* in zephyr/dts/arm/nordic/nrf91_ns.dtsi:60 */

			/* node '/soc/flash-controller@40039000/flash@0' defined in zephyr/dts/arm/nordic/nrf91_ns.dtsi:62 */
			flash0: flash@0 {
				compatible = "soc-nv-flash";   /* in zephyr/dts/arm/nordic/nrf91_ns.dtsi:63 */
				erase-block-size = < 0x1000 >; /* in zephyr/dts/arm/nordic/nrf91_ns.dtsi:64 */
				write-block-size = < 0x4 >;    /* in zephyr/dts/arm/nordic/nrf91_ns.dtsi:65 */
				reg = < 0x0 0x100000 >;        /* in zephyr/dts/arm/nordic/nrf91_ns.dtsi:66 */
				ranges = < 0x0 0x0 0x100000 >; /* in zephyr/dts/arm/nordic/nrf91_ns.dtsi:67 */
				status = "okay";               /* in zephyr/dts/arm/nordic/nrf91_ns.dtsi:68 */
				#address-cells = < 0x1 >;      /* in zephyr/dts/arm/nordic/nrf91_ns.dtsi:69 */
				#size-cells = < 0x1 >;         /* in zephyr/dts/arm/nordic/nrf91_ns.dtsi:70 */

				/* node '/soc/flash-controller@40039000/flash@0/partitions' defined in zephyr/dts/vendor/nordic/nrf91xx_partition.dtsi:27 */
				partitions {
					ranges;                   /* in zephyr/dts/vendor/nordic/nrf91xx_partition.dtsi:28 */
					#address-cells = < 0x1 >; /* in zephyr/dts/vendor/nordic/nrf91xx_partition.dtsi:29 */
					#size-cells = < 0x1 >;    /* in zephyr/dts/vendor/nordic/nrf91xx_partition.dtsi:30 */

					/* node '/soc/flash-controller@40039000/flash@0/partitions/partition@0' defined in zephyr/dts/vendor/nordic/nrf91xx_partition.dtsi:32 */
					boot_partition: partition@0 {
						compatible = "zephyr,mapped-partition"; /* in zephyr/dts/vendor/nordic/nrf91xx_partition.dtsi:33 */
						label = "mcuboot";                      /* in zephyr/dts/vendor/nordic/nrf91xx_partition.dtsi:34 */
						reg = < 0x0 0x10000 >;                  /* in zephyr/dts/vendor/nordic/nrf91xx_partition.dtsi:35 */
					};

					/* node '/soc/flash-controller@40039000/flash@0/partitions/partition@10000' defined in zephyr/dts/vendor/nordic/nrf91xx_partition.dtsi:38 */
					slot0_partition: partition@10000 {
						compatible = "zephyr,mapped-partition"; /* in zephyr/dts/vendor/nordic/nrf91xx_partition.dtsi:39 */
						label = "image-0";                      /* in zephyr/dts/vendor/nordic/nrf91xx_partition.dtsi:40 */
						reg = < 0x10000 0x70000 >;              /* in zephyr/dts/vendor/nordic/nrf91xx_partition.dtsi:41 */
						ranges = < 0x0 0x10000 0x70000 >;       /* in zephyr/dts/vendor/nordic/nrf91xx_partition.dtsi:42 */
						#address-cells = < 0x1 >;               /* in zephyr/dts/vendor/nordic/nrf91xx_partition.dtsi:43 */
						#size-cells = < 0x1 >;                  /* in zephyr/dts/vendor/nordic/nrf91xx_partition.dtsi:44 */

						/* node '/soc/flash-controller@40039000/flash@0/partitions/partition@10000/partition@0' defined in zephyr/dts/vendor/nordic/nrf91xx_partition.dtsi:46 */
						slot0_s_partition: partition@0 {
							compatible = "zephyr,mapped-partition"; /* in zephyr/dts/vendor/nordic/nrf91xx_partition.dtsi:47 */
							label = "image-0-secure";               /* in zephyr/dts/vendor/nordic/nrf91xx_partition.dtsi:48 */
							reg = < 0x0 0x40000 >;                  /* in zephyr/dts/vendor/nordic/nrf91xx_partition.dtsi:49 */
						};

						/* node '/soc/flash-controller@40039000/flash@0/partitions/partition@10000/partition@40000' defined in zephyr/dts/vendor/nordic/nrf91xx_partition.dtsi:52 */
						slot0_ns_partition: partition@40000 {
							compatible = "zephyr,mapped-partition"; /* in zephyr/dts/vendor/nordic/nrf91xx_partition.dtsi:53 */
							label = "image-0-nonsecure";            /* in zephyr/dts/vendor/nordic/nrf91xx_partition.dtsi:54 */
							reg = < 0x40000 0x30000 >;              /* in zephyr/dts/vendor/nordic/nrf91xx_partition.dtsi:55 */
						};
					};

					/* node '/soc/flash-controller@40039000/flash@0/partitions/partition@80000' defined in zephyr/dts/vendor/nordic/nrf91xx_partition.dtsi:59 */
					slot1_partition: partition@80000 {
						compatible = "zephyr,mapped-partition"; /* in zephyr/dts/vendor/nordic/nrf91xx_partition.dtsi:60 */
						label = "image-1";                      /* in zephyr/dts/vendor/nordic/nrf91xx_partition.dtsi:61 */
						reg = < 0x80000 0x70000 >;              /* in zephyr/dts/vendor/nordic/nrf91xx_partition.dtsi:62 */
						ranges = < 0x0 0x80000 0x70000 >;       /* in zephyr/dts/vendor/nordic/nrf91xx_partition.dtsi:63 */
						#address-cells = < 0x1 >;               /* in zephyr/dts/vendor/nordic/nrf91xx_partition.dtsi:64 */
						#size-cells = < 0x1 >;                  /* in zephyr/dts/vendor/nordic/nrf91xx_partition.dtsi:65 */

						/* node '/soc/flash-controller@40039000/flash@0/partitions/partition@80000/partition@0' defined in zephyr/dts/vendor/nordic/nrf91xx_partition.dtsi:67 */
						slot1_s_partition: partition@0 {
							compatible = "zephyr,mapped-partition"; /* in zephyr/dts/vendor/nordic/nrf91xx_partition.dtsi:68 */
							label = "image-1-secure";               /* in zephyr/dts/vendor/nordic/nrf91xx_partition.dtsi:69 */
							reg = < 0x0 0x40000 >;                  /* in zephyr/dts/vendor/nordic/nrf91xx_partition.dtsi:70 */
						};

						/* node '/soc/flash-controller@40039000/flash@0/partitions/partition@80000/partition@40000' defined in zephyr/dts/vendor/nordic/nrf91xx_partition.dtsi:73 */
						slot1_ns_partition: partition@40000 {
							compatible = "zephyr,mapped-partition"; /* in zephyr/dts/vendor/nordic/nrf91xx_partition.dtsi:74 */
							label = "image-1-nonsecure";            /* in zephyr/dts/vendor/nordic/nrf91xx_partition.dtsi:75 */
							reg = < 0x40000 0x30000 >;              /* in zephyr/dts/vendor/nordic/nrf91xx_partition.dtsi:76 */
						};
					};

					/* node '/soc/flash-controller@40039000/flash@0/partitions/partition@f0000' defined in zephyr/dts/vendor/nordic/nrf91xx_partition.dtsi:80 */
					tfm_ps_partition: partition@f0000 {
						compatible = "zephyr,mapped-partition"; /* in zephyr/dts/vendor/nordic/nrf91xx_partition.dtsi:81 */
						label = "tfm-ps";                       /* in zephyr/dts/vendor/nordic/nrf91xx_partition.dtsi:82 */
						reg = < 0xf0000 0x4000 >;               /* in zephyr/dts/vendor/nordic/nrf91xx_partition.dtsi:83 */
					};

					/* node '/soc/flash-controller@40039000/flash@0/partitions/partition@f4000' defined in zephyr/dts/vendor/nordic/nrf91xx_partition.dtsi:86 */
					tfm_its_partition: partition@f4000 {
						compatible = "zephyr,mapped-partition"; /* in zephyr/dts/vendor/nordic/nrf91xx_partition.dtsi:87 */
						label = "tfm-its";                      /* in zephyr/dts/vendor/nordic/nrf91xx_partition.dtsi:88 */
						reg = < 0xf4000 0x2000 >;               /* in zephyr/dts/vendor/nordic/nrf91xx_partition.dtsi:89 */
					};

					/* node '/soc/flash-controller@40039000/flash@0/partitions/partition@f6000' defined in zephyr/dts/vendor/nordic/nrf91xx_partition.dtsi:92 */
					tfm_otp_partition: partition@f6000 {
						compatible = "zephyr,mapped-partition"; /* in zephyr/dts/vendor/nordic/nrf91xx_partition.dtsi:93 */
						label = "tfm-otp";                      /* in zephyr/dts/vendor/nordic/nrf91xx_partition.dtsi:94 */
						reg = < 0xf6000 0x2000 >;               /* in zephyr/dts/vendor/nordic/nrf91xx_partition.dtsi:95 */
					};

					/* node '/soc/flash-controller@40039000/flash@0/partitions/partition@f8000' defined in zephyr/dts/vendor/nordic/nrf91xx_partition.dtsi:98 */
					storage_partition: partition@f8000 {
						compatible = "zephyr,mapped-partition"; /* in zephyr/dts/vendor/nordic/nrf91xx_partition.dtsi:99 */
						label = "storage";                      /* in zephyr/dts/vendor/nordic/nrf91xx_partition.dtsi:100 */
						reg = < 0xf8000 0x8000 >;               /* in zephyr/dts/vendor/nordic/nrf91xx_partition.dtsi:101 */
					};
				};
			};
		};

		/* node '/soc/gpiote@40031000' defined in zephyr/dts/arm/nordic/nrf91_ns.dtsi:79 */
		gpiote: gpiote1: gpiote@40031000 {
			compatible = "nordic,nrf-gpiote"; /* in zephyr/dts/arm/nordic/nrf91_ns.dtsi:80 */
			reg = < 0x40031000 0x1000 >;      /* in zephyr/dts/arm/nordic/nrf91_ns.dtsi:81 */
			interrupts = < 0x31 0x5 >;        /* in zephyr/dts/arm/nordic/nrf91_ns.dtsi:82 */
			instance = < 0x1 >;               /* in zephyr/dts/arm/nordic/nrf91_ns.dtsi:84 */
			status = "okay";                  /* in zephyr/boards/nordic/nrf9151dk/nrf9151dk_nrf9151_common.dtsi:148 */
			phandle = < 0xe >;                /* in zephyr/dts/arm/nordic/nrf91_peripherals.dtsi:303 */
		};
	};

	/* node '/pin-controller' defined in zephyr/dts/vendor/nordic/nrf_common.dtsi:26 */
	pinctrl: pin-controller {
		compatible = "nordic,nrf-pinctrl"; /* in zephyr/dts/vendor/nordic/nrf_common.dtsi:31 */

		/* node '/pin-controller/uart0_default' defined in zephyr/boards/nordic/nrf9151dk/nrf9151dk_nrf9151_common-pinctrl.dtsi:7 */
		uart0_default: uart0_default {
			phandle = < 0x2 >; /* in zephyr/boards/nordic/nrf9151dk/nrf9151dk_nrf9151_common.dtsi:158 */

			/* node '/pin-controller/uart0_default/group1' defined in zephyr/boards/nordic/nrf9151dk/nrf9151dk_nrf9151_common-pinctrl.dtsi:8 */
			group1 {
				psels = < 0x1b >,
				        < 0x200000e >; /* in zephyr/boards/nordic/nrf9151dk/nrf9151dk_nrf9151_common-pinctrl.dtsi:9 */
			};

			/* node '/pin-controller/uart0_default/group2' defined in zephyr/boards/nordic/nrf9151dk/nrf9151dk_nrf9151_common-pinctrl.dtsi:13 */
			group2 {
				psels = < 0x100001a >,
				        < 0x300000f >; /* in zephyr/boards/nordic/nrf9151dk/nrf9151dk_nrf9151_common-pinctrl.dtsi:14 */
				bias-pull-up;          /* in zephyr/boards/nordic/nrf9151dk/nrf9151dk_nrf9151_common-pinctrl.dtsi:16 */
			};
		};

		/* node '/pin-controller/uart0_sleep' defined in zephyr/boards/nordic/nrf9151dk/nrf9151dk_nrf9151_common-pinctrl.dtsi:20 */
		uart0_sleep: uart0_sleep {
			phandle = < 0x3 >; /* in zephyr/boards/nordic/nrf9151dk/nrf9151dk_nrf9151_common.dtsi:159 */

			/* node '/pin-controller/uart0_sleep/group1' defined in zephyr/boards/nordic/nrf9151dk/nrf9151dk_nrf9151_common-pinctrl.dtsi:21 */
			group1 {
				psels = < 0x100001a >,
				        < 0x200000e >,
				        < 0x300000f >; /* in zephyr/boards/nordic/nrf9151dk/nrf9151dk_nrf9151_common-pinctrl.dtsi:22 */
				low-power-enable;      /* in zephyr/boards/nordic/nrf9151dk/nrf9151dk_nrf9151_common-pinctrl.dtsi:25 */
			};

			/* node '/pin-controller/uart0_sleep/group2' defined in zephyr/boards/nordic/nrf9151dk/nrf9151dk_nrf9151_common-pinctrl.dtsi:28 */
			group2 {
				psels = < 0x1b >; /* in zephyr/boards/nordic/nrf9151dk/nrf9151dk_nrf9151_common-pinctrl.dtsi:29 */
				low-power-enable; /* in zephyr/boards/nordic/nrf9151dk/nrf9151dk_nrf9151_common-pinctrl.dtsi:30 */
				bias-pull-up;     /* in zephyr/boards/nordic/nrf9151dk/nrf9151dk_nrf9151_common-pinctrl.dtsi:31 */
			};
		};

		/* node '/pin-controller/uart1_default' defined in zephyr/boards/nordic/nrf9151dk/nrf9151dk_nrf9151_common-pinctrl.dtsi:35 */
		uart1_default: uart1_default {
			phandle = < 0x4 >; /* in zephyr/boards/nordic/nrf9151dk/nrf9151dk_nrf9151_common.dtsi:166 */

			/* node '/pin-controller/uart1_default/group1' defined in zephyr/boards/nordic/nrf9151dk/nrf9151dk_nrf9151_common-pinctrl.dtsi:36 */
			group1 {
				psels = < 0x1d >,
				        < 0x2000010 >; /* in zephyr/boards/nordic/nrf9151dk/nrf9151dk_nrf9151_common-pinctrl.dtsi:37 */
			};

			/* node '/pin-controller/uart1_default/group2' defined in zephyr/boards/nordic/nrf9151dk/nrf9151dk_nrf9151_common-pinctrl.dtsi:41 */
			group2 {
				psels = < 0x100001c >,
				        < 0x3000011 >; /* in zephyr/boards/nordic/nrf9151dk/nrf9151dk_nrf9151_common-pinctrl.dtsi:42 */
				bias-pull-up;          /* in zephyr/boards/nordic/nrf9151dk/nrf9151dk_nrf9151_common-pinctrl.dtsi:44 */
			};
		};

		/* node '/pin-controller/uart1_sleep' defined in zephyr/boards/nordic/nrf9151dk/nrf9151dk_nrf9151_common-pinctrl.dtsi:48 */
		uart1_sleep: uart1_sleep {
			phandle = < 0x5 >; /* in zephyr/boards/nordic/nrf9151dk/nrf9151dk_nrf9151_common.dtsi:167 */

			/* node '/pin-controller/uart1_sleep/group1' defined in zephyr/boards/nordic/nrf9151dk/nrf9151dk_nrf9151_common-pinctrl.dtsi:49 */
			group1 {
				psels = < 0x1d >,
				        < 0x100001c >,
				        < 0x2000010 >,
				        < 0x3000011 >; /* in zephyr/boards/nordic/nrf9151dk/nrf9151dk_nrf9151_common-pinctrl.dtsi:50 */
				low-power-enable;      /* in zephyr/boards/nordic/nrf9151dk/nrf9151dk_nrf9151_common-pinctrl.dtsi:54 */
			};
		};

		/* node '/pin-controller/i2c2_default' defined in zephyr/boards/nordic/nrf9151dk/nrf9151dk_nrf9151_common-pinctrl.dtsi:58 */
		i2c2_default: i2c2_default {
			phandle = < 0x6 >; /* in zephyr/boards/nordic/nrf9151dk/nrf9151dk_nrf9151_common.dtsi:174 */

			/* node '/pin-controller/i2c2_default/group1' defined in zephyr/boards/nordic/nrf9151dk/nrf9151dk_nrf9151_common-pinctrl.dtsi:59 */
			group1 {
				psels = < 0xc00001e >,
				        < 0xb00001f >; /* in zephyr/boards/nordic/nrf9151dk/nrf9151dk_nrf9151_common-pinctrl.dtsi:60 */
			};
		};

		/* node '/pin-controller/i2c2_sleep' defined in zephyr/boards/nordic/nrf9151dk/nrf9151dk_nrf9151_common-pinctrl.dtsi:65 */
		i2c2_sleep: i2c2_sleep {
			phandle = < 0x7 >; /* in zephyr/boards/nordic/nrf9151dk/nrf9151dk_nrf9151_common.dtsi:175 */

			/* node '/pin-controller/i2c2_sleep/group1' defined in zephyr/boards/nordic/nrf9151dk/nrf9151dk_nrf9151_common-pinctrl.dtsi:66 */
			group1 {
				psels = < 0xc00001e >,
				        < 0xb00001f >; /* in zephyr/boards/nordic/nrf9151dk/nrf9151dk_nrf9151_common-pinctrl.dtsi:67 */
				low-power-enable;      /* in zephyr/boards/nordic/nrf9151dk/nrf9151dk_nrf9151_common-pinctrl.dtsi:69 */
			};
		};

		/* node '/pin-controller/pwm0_default' defined in zephyr/boards/nordic/nrf9151dk/nrf9151dk_nrf9151_common-pinctrl.dtsi:73 */
		pwm0_default: pwm0_default {
			phandle = < 0xc >; /* in zephyr/boards/nordic/nrf9151dk/nrf9151dk_nrf9151_common.dtsi:192 */

			/* node '/pin-controller/pwm0_default/group1' defined in zephyr/boards/nordic/nrf9151dk/nrf9151dk_nrf9151_common-pinctrl.dtsi:74 */
			group1 {
				psels = < 0x16000000 >; /* in zephyr/boards/nordic/nrf9151dk/nrf9151dk_nrf9151_common-pinctrl.dtsi:75 */
			};
		};

		/* node '/pin-controller/pwm0_sleep' defined in zephyr/boards/nordic/nrf9151dk/nrf9151dk_nrf9151_common-pinctrl.dtsi:79 */
		pwm0_sleep: pwm0_sleep {
			phandle = < 0xd >; /* in zephyr/boards/nordic/nrf9151dk/nrf9151dk_nrf9151_common.dtsi:193 */

			/* node '/pin-controller/pwm0_sleep/group1' defined in zephyr/boards/nordic/nrf9151dk/nrf9151dk_nrf9151_common-pinctrl.dtsi:80 */
			group1 {
				psels = < 0x16000000 >; /* in zephyr/boards/nordic/nrf9151dk/nrf9151dk_nrf9151_common-pinctrl.dtsi:81 */
				low-power-enable;       /* in zephyr/boards/nordic/nrf9151dk/nrf9151dk_nrf9151_common-pinctrl.dtsi:82 */
			};
		};

		/* node '/pin-controller/spi3_default' defined in zephyr/boards/nordic/nrf9151dk/nrf9151dk_nrf9151_common-pinctrl.dtsi:86 */
		spi3_default: spi3_default {
			phandle = < 0xa >; /* in zephyr/boards/nordic/nrf9151dk/nrf9151dk_nrf9151_common.dtsi:202 */

			/* node '/pin-controller/spi3_default/group1' defined in zephyr/boards/nordic/nrf9151dk/nrf9151dk_nrf9151_common-pinctrl.dtsi:87 */
			group1 {
				psels = < 0x400000d >,
				        < 0x600000c >,
				        < 0x500000b >;       /* in zephyr/boards/nordic/nrf9151dk/nrf9151dk_nrf9151_common-pinctrl.dtsi:88 */
				nordic,drive-mode = < 0x3 >; /* in zephyr/boards/nordic/nrf9151dk/nrf9151dk_nrf9151_common-pinctrl.dtsi:91 */
			};
		};

		/* node '/pin-controller/spi3_sleep' defined in zephyr/boards/nordic/nrf9151dk/nrf9151dk_nrf9151_common-pinctrl.dtsi:95 */
		spi3_sleep: spi3_sleep {
			phandle = < 0xb >; /* in zephyr/boards/nordic/nrf9151dk/nrf9151dk_nrf9151_common.dtsi:203 */

			/* node '/pin-controller/spi3_sleep/group1' defined in zephyr/boards/nordic/nrf9151dk/nrf9151dk_nrf9151_common-pinctrl.dtsi:96 */
			group1 {
				psels = < 0x400000d >,
				        < 0x600000c >,
				        < 0x500000b >; /* in zephyr/boards/nordic/nrf9151dk/nrf9151dk_nrf9151_common-pinctrl.dtsi:97 */
				low-power-enable;      /* in zephyr/boards/nordic/nrf9151dk/nrf9151dk_nrf9151_common-pinctrl.dtsi:100 */
			};
		};
	};

	/* node '/entropy_bt_hci' defined in zephyr/dts/vendor/nordic/nrf_common.dtsi:34 */
	rng_hci: entropy_bt_hci {
		compatible = "zephyr,bt-hci-entropy"; /* in zephyr/dts/vendor/nordic/nrf_common.dtsi:35 */
		status = "disabled";                  /* in zephyr/dts/vendor/nordic/nrf_common.dtsi:36 */
	};

	/* node '/sw-pwm' defined in zephyr/dts/vendor/nordic/nrf_common.dtsi:39 */
	sw_pwm: sw-pwm {
		compatible = "nordic,nrf-sw-pwm"; /* in zephyr/dts/vendor/nordic/nrf_common.dtsi:40 */
		status = "disabled";              /* in zephyr/dts/vendor/nordic/nrf_common.dtsi:41 */
		generator = < &timer1 >;          /* in zephyr/dts/vendor/nordic/nrf_common.dtsi:42 */
		clock-prescaler = < 0x0 >;        /* in zephyr/dts/vendor/nordic/nrf_common.dtsi:43 */
		#pwm-cells = < 0x3 >;             /* in zephyr/dts/vendor/nordic/nrf_common.dtsi:44 */
	};

	/* node '/cpus' defined in zephyr/dts/arm/nordic/nrf91_ns.dtsi:12 */
	cpus {
		#address-cells = < 0x1 >; /* in zephyr/dts/arm/nordic/nrf91_ns.dtsi:13 */
		#size-cells = < 0x0 >;    /* in zephyr/dts/arm/nordic/nrf91_ns.dtsi:14 */

		/* node '/cpus/cpu@0' defined in zephyr/dts/arm/nordic/nrf91_ns.dtsi:16 */
		cpu@0 {
			device_type = "cpu";            /* in zephyr/dts/arm/nordic/nrf91_ns.dtsi:17 */
			compatible = "arm,cortex-m33f"; /* in zephyr/dts/arm/nordic/nrf91_ns.dtsi:18 */
			reg = < 0x0 >;                  /* in zephyr/dts/arm/nordic/nrf91_ns.dtsi:19 */
			#address-cells = < 0x1 >;       /* in zephyr/dts/arm/nordic/nrf91_ns.dtsi:20 */
			#size-cells = < 0x1 >;          /* in zephyr/dts/arm/nordic/nrf91_ns.dtsi:21 */

			/* node '/cpus/cpu@0/mpu@e000ed90' defined in zephyr/dts/arm/nordic/nrf91_ns.dtsi:23 */
			mpu: mpu@e000ed90 {
				compatible = "arm,armv8m-mpu"; /* in zephyr/dts/arm/nordic/nrf91_ns.dtsi:24 */
				reg = < 0xe000ed90 0x40 >;     /* in zephyr/dts/arm/nordic/nrf91_ns.dtsi:25 */
			};
		};
	};

	/* node '/psa-rng' defined in zephyr/dts/arm/nordic/nrf91_ns.dtsi:88 */
	psa_rng: psa-rng {
		compatible = "zephyr,psa-crypto-rng"; /* in zephyr/dts/arm/nordic/nrf91_ns.dtsi:89 */
		status = "okay";                      /* in zephyr/dts/arm/nordic/nrf91_ns.dtsi:90 */
	};

	/* node '/leds' defined in zephyr/boards/nordic/nrf9151dk/nrf9151dk_nrf9151_common.dtsi:20 */
	leds {
		compatible = "gpio-leds"; /* in zephyr/boards/nordic/nrf9151dk/nrf9151dk_nrf9151_common.dtsi:21 */

		/* node '/leds/led_0' defined in zephyr/boards/nordic/nrf9151dk/nrf9151dk_nrf9151_common.dtsi:23 */
		led0: led_0 {
			gpios = < &gpio0 0x0 0x0 >; /* in zephyr/boards/nordic/nrf9151dk/nrf9151dk_nrf9151_common.dtsi:24 */
			label = "Green LED 1";      /* in zephyr/boards/nordic/nrf9151dk/nrf9151dk_nrf9151_common.dtsi:25 */
		};

		/* node '/leds/led_1' defined in zephyr/boards/nordic/nrf9151dk/nrf9151dk_nrf9151_common.dtsi:28 */
		led1: led_1 {
			gpios = < &gpio0 0x1 0x0 >; /* in zephyr/boards/nordic/nrf9151dk/nrf9151dk_nrf9151_common.dtsi:29 */
			label = "Green LED 2";      /* in zephyr/boards/nordic/nrf9151dk/nrf9151dk_nrf9151_common.dtsi:30 */
		};

		/* node '/leds/led_2' defined in zephyr/boards/nordic/nrf9151dk/nrf9151dk_nrf9151_common.dtsi:33 */
		led2: led_2 {
			gpios = < &gpio0 0x4 0x0 >; /* in zephyr/boards/nordic/nrf9151dk/nrf9151dk_nrf9151_common.dtsi:34 */
			label = "Green LED 3";      /* in zephyr/boards/nordic/nrf9151dk/nrf9151dk_nrf9151_common.dtsi:35 */
		};

		/* node '/leds/led_3' defined in zephyr/boards/nordic/nrf9151dk/nrf9151dk_nrf9151_common.dtsi:38 */
		led3: led_3 {
			gpios = < &gpio0 0x5 0x0 >; /* in zephyr/boards/nordic/nrf9151dk/nrf9151dk_nrf9151_common.dtsi:39 */
			label = "Green LED 4";      /* in zephyr/boards/nordic/nrf9151dk/nrf9151dk_nrf9151_common.dtsi:40 */
		};
	};

	/* node '/pwmleds' defined in zephyr/boards/nordic/nrf9151dk/nrf9151dk_nrf9151_common.dtsi:44 */
	pwmleds {
		compatible = "pwm-leds"; /* in zephyr/boards/nordic/nrf9151dk/nrf9151dk_nrf9151_common.dtsi:45 */

		/* node '/pwmleds/pwm_led_0' defined in zephyr/boards/nordic/nrf9151dk/nrf9151dk_nrf9151_common.dtsi:47 */
		pwm_led0: pwm_led_0 {
			pwms = < &pwm0 0x0 0x1312d00 0x0 >; /* in zephyr/boards/nordic/nrf9151dk/nrf9151dk_nrf9151_common.dtsi:48 */
		};
	};

	/* node '/buttons' defined in zephyr/boards/nordic/nrf9151dk/nrf9151dk_nrf9151_common.dtsi:52 */
	buttons {
		compatible = "gpio-keys"; /* in zephyr/boards/nordic/nrf9151dk/nrf9151dk_nrf9151_common.dtsi:53 */

		/* node '/buttons/button_0' defined in zephyr/boards/nordic/nrf9151dk/nrf9151dk_nrf9151_common.dtsi:55 */
		button0: button_0 {
			gpios = < &gpio0 0x8 0x11 >; /* in zephyr/boards/nordic/nrf9151dk/nrf9151dk_nrf9151_common.dtsi:56 */
			label = "Push button 1";     /* in zephyr/boards/nordic/nrf9151dk/nrf9151dk_nrf9151_common.dtsi:57 */
			zephyr,code = < 0xb >;       /* in zephyr/boards/nordic/nrf9151dk/nrf9151dk_nrf9151_common.dtsi:58 */
		};

		/* node '/buttons/button_1' defined in zephyr/boards/nordic/nrf9151dk/nrf9151dk_nrf9151_common.dtsi:61 */
		button1: button_1 {
			gpios = < &gpio0 0x9 0x11 >; /* in zephyr/boards/nordic/nrf9151dk/nrf9151dk_nrf9151_common.dtsi:62 */
			label = "Push button 2";     /* in zephyr/boards/nordic/nrf9151dk/nrf9151dk_nrf9151_common.dtsi:63 */
			zephyr,code = < 0x2 >;       /* in zephyr/boards/nordic/nrf9151dk/nrf9151dk_nrf9151_common.dtsi:64 */
		};

		/* node '/buttons/button_2' defined in zephyr/boards/nordic/nrf9151dk/nrf9151dk_nrf9151_common.dtsi:67 */
		button2: button_2 {
			gpios = < &gpio0 0x12 0x11 >; /* in zephyr/boards/nordic/nrf9151dk/nrf9151dk_nrf9151_common.dtsi:68 */
			label = "Push button 3";      /* in zephyr/boards/nordic/nrf9151dk/nrf9151dk_nrf9151_common.dtsi:69 */
			zephyr,code = < 0x3 >;        /* in zephyr/boards/nordic/nrf9151dk/nrf9151dk_nrf9151_common.dtsi:70 */
		};

		/* node '/buttons/button_3' defined in zephyr/boards/nordic/nrf9151dk/nrf9151dk_nrf9151_common.dtsi:73 */
		button3: button_3 {
			gpios = < &gpio0 0x13 0x11 >; /* in zephyr/boards/nordic/nrf9151dk/nrf9151dk_nrf9151_common.dtsi:74 */
			label = "Push button 4";      /* in zephyr/boards/nordic/nrf9151dk/nrf9151dk_nrf9151_common.dtsi:75 */
			zephyr,code = < 0x4 >;        /* in zephyr/boards/nordic/nrf9151dk/nrf9151dk_nrf9151_common.dtsi:76 */
		};
	};

	/* node '/gpio-reset' defined in zephyr/boards/nordic/nrf9151dk/nrf9151dk_nrf9151_common.dtsi:80 */
	nrf5340_reset: gpio-reset {
		compatible = "nordic,nrf9151dk-nrf5340-reset"; /* in zephyr/boards/nordic/nrf9151dk/nrf9151dk_nrf9151_common.dtsi:81 */
		status = "disabled";                           /* in zephyr/boards/nordic/nrf9151dk/nrf9151dk_nrf9151_common.dtsi:82 */
		gpios = < &gpio0 0x15 0x1 >;                   /* in zephyr/boards/nordic/nrf9151dk/nrf9151dk_nrf9151_common.dtsi:83 */
	};

	/* node '/connector' defined in zephyr/boards/nordic/nrf9151dk/nrf9151dk_nrf9151_common.dtsi:86 */
	arduino_header: connector {
		compatible = "arduino-header-r3";          /* in zephyr/boards/nordic/nrf9151dk/nrf9151dk_nrf9151_common.dtsi:87 */
		#gpio-cells = < 0x2 >;                     /* in zephyr/boards/nordic/nrf9151dk/nrf9151dk_nrf9151_common.dtsi:88 */
		gpio-map-mask = < 0xffffffff 0xffffffc0 >; /* in zephyr/boards/nordic/nrf9151dk/nrf9151dk_nrf9151_common.dtsi:89 */
		gpio-map-pass-thru = < 0x0 0x3f >;         /* in zephyr/boards/nordic/nrf9151dk/nrf9151dk_nrf9151_common.dtsi:90 */
		gpio-map = < 0x0 0x0 &gpio0 0xe 0x0 >,
		           < 0x1 0x0 &gpio0 0xf 0x0 >,
		           < 0x2 0x0 &gpio0 0x10 0x0 >,
		           < 0x3 0x0 &gpio0 0x11 0x0 >,
		           < 0x4 0x0 &gpio0 0x12 0x0 >,
		           < 0x5 0x0 &gpio0 0x13 0x0 >,
		           < 0x6 0x0 &gpio0 0x0 0x0 >,
		           < 0x7 0x0 &gpio0 0x1 0x0 >,
		           < 0x8 0x0 &gpio0 0x2 0x0 >,
		           < 0x9 0x0 &gpio0 0x3 0x0 >,
		           < 0xa 0x0 &gpio0 0x4 0x0 >,
		           < 0xb 0x0 &gpio0 0x5 0x0 >,
		           < 0xc 0x0 &gpio0 0x6 0x0 >,
		           < 0xd 0x0 &gpio0 0x7 0x0 >,
		           < 0xe 0x0 &gpio0 0x8 0x0 >,
		           < 0xf 0x0 &gpio0 0x9 0x0 >,
		           < 0x10 0x0 &gpio0 0xa 0x0 >,
		           < 0x11 0x0 &gpio0 0xb 0x0 >,
		           < 0x12 0x0 &gpio0 0xc 0x0 >,
		           < 0x13 0x0 &gpio0 0xd 0x0 >,
		           < 0x14 0x0 &gpio0 0x1e 0x0 >,
		           < 0x15 0x0 &gpio0 0x1f 0x0 >;   /* in zephyr/boards/nordic/nrf9151dk/nrf9151dk_nrf9151_common.dtsi:91 */
		phandle = < 0x9 >;                         /* in zephyr/boards/nordic/nrf9151dk/nrf9151dk_nrf9151_common.dtsi:200 */
	};

	/* node '/analog-connector' defined in zephyr/boards/nordic/nrf9151dk/nrf9151dk_nrf9151_common.dtsi:115 */
	arduino_adc: analog-connector {
		compatible = "arduino,uno-adc";    /* in zephyr/boards/nordic/nrf9151dk/nrf9151dk_nrf9151_common.dtsi:116 */
		#io-channel-cells = < 0x1 >;       /* in zephyr/boards/nordic/nrf9151dk/nrf9151dk_nrf9151_common.dtsi:117 */
		io-channel-map = < 0x0 &adc 0x1 >,
		                 < 0x1 &adc 0x2 >,
		                 < 0x2 &adc 0x3 >,
		                 < 0x3 &adc 0x4 >,
		                 < 0x4 &adc 0x5 >,
		                 < 0x5 &adc 0x6 >; /* in zephyr/boards/nordic/nrf9151dk/nrf9151dk_nrf9151_common.dtsi:118 */
	};
};
